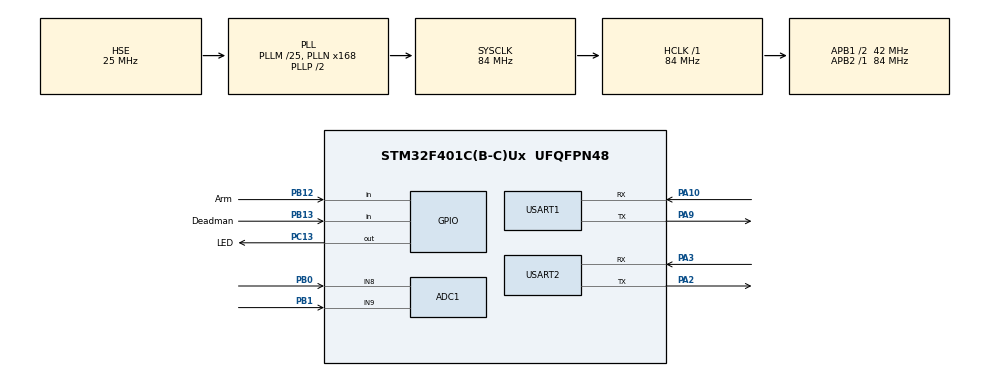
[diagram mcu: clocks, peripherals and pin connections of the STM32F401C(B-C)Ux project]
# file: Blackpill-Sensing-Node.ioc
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ADC1.Channel-0\#ChannelRegularConversion=ADC_CHANNEL_9
ADC1.Channel-1\#ChannelRegularConversion=ADC_CHANNEL_8
ADC1.DiscontinuousConvMode=ENABLE
ADC1.NbrOfDiscConversion=1
ADC1.EOCSelection=ADC_EOC_SINGLE_CONV
ADC1.NbrOfConversion=2
ADC1.NbrOfConversionFlag=1
ADC1.Rank-0\#ChannelRegularConversion=1
ADC1.Rank-1\#ChannelRegularConversion=2
ADC1.SamplingTime-0\#ChannelRegularConversion=ADC_SAMPLETIME_84CYCLES
ADC1.SamplingTime-1\#ChannelRegularConversion=ADC_SAMPLETIME_84CYCLES
ADC1.ScanConvMode=ENABLE
ADC1.master=1
FREERTOS.Tasks01=defaultTask,24,128,StartDefaultTask,Default,NULL,Dynamic,NULL,NULL
Mcu.Family=STM32F4
Mcu.Name=STM32F401C(B-C)Ux
Mcu.Package=UFQFPN48
NVIC.PriorityGroup=NVIC_PRIORITYGROUP_4
NVIC.TIM1_TRG_COM_TIM11_IRQn=true\:15\:0\:false\:false\:true\:false\:false\:true\:true
NVIC.TimeBase=TIM1_TRG_COM_TIM11_IRQn
NVIC.TimeBaseIP=TIM11
NVIC.USART1_IRQn=true\:5\:0\:false\:false\:true\:true\:true\:true\:true
PA10.Mode=Asynchronous
PA10.GPIO_PuPd=GPIO_PULLUP
PA10.Signal=USART1_RX
PA13.Mode=Serial_Wire
PA13.Signal=SYS_JTMS-SWDIO
PA14.Mode=Serial_Wire
PA14.Signal=SYS_JTCK-SWCLK
PA2.Mode=Asynchronous
PA2.Signal=USART2_TX
PA3.Mode=Asynchronous
PA3.Signal=USART2_RX
PA9.Mode=Asynchronous
PA9.Signal=USART1_TX
PB0.Signal=ADCx_IN8
PB1.Signal=ADCx_IN9
PB12.GPIO_Label=Arm
PB12.GPIO_PuPd=GPIO_PULLUP
PB12.Signal=GPIO_Input
PB13.GPIO_Label=Deadman
PB13.GPIO_PuPd=GPIO_PULLUP
PB13.Signal=GPIO_Input
PC13-ANTI_TAMP.GPIO_Label=LED
PC13-ANTI_TAMP.PinState=GPIO_PIN_SET
PC13-ANTI_TAMP.Signal=GPIO_Output
PH0\ -\ OSC_IN.Mode=HSE-External-Oscillator
PH0\ -\ OSC_IN.Signal=RCC_OSC_IN
PH1\ -\ OSC_OUT.Mode=HSE-External-Oscillator
PH1\ -\ OSC_OUT.Signal=RCC_OSC_OUT
ProjectManager.HeapSize=0x200
ProjectManager.StackSize=0x400
ProjectManager.TargetToolchain=EWARM V8.50
RCC.48MHZClocksFreq_Value=42000000
RCC.AHBFreq_Value=84000000
RCC.APB1CLKDivider=RCC_HCLK_DIV2
RCC.APB1Freq_Value=42000000
RCC.APB1TimFreq_Value=84000000
RCC.APB2Freq_Value=84000000
RCC.APB2TimFreq_Value=84000000
RCC.CortexFreq_Value=84000000
RCC.HCLKFreq_Value=84000000
RCC.HSE_VALUE=25000000
RCC.HSI_VALUE=16000000
RCC.LSE_VALUE=32768
RCC.PLLM=25
RCC.PLLN=168
RCC.PLLSourceVirtual=RCC_PLLSOURCE_HSE
RCC.SYSCLKFreq_VALUE=84000000
RCC.SYSCLKSource=RCC_SYSCLKSOURCE_PLLCLK
RCC.VCOOutputFreq_Value=168000000
SH.ADCx_IN8.0=ADC1_IN8,IN8
SH.ADCx_IN9.0=ADC1_IN9,IN9
USART1.VirtualMode=VM_ASYNC
USART2.VirtualMode=VM_ASYNC
VP_FREERTOS_VS_CMSIS_V2.Mode=CMSIS_V2
VP_SYS_VS_tim11.Mode=TIM11
board=custom

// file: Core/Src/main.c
/* USER CODE BEGIN Header */
/**
  ******************************************************************************
  * @file           : main.c
  * @brief          : Main program body
  ******************************************************************************
  * @attention
  *
  * Copyright (c) 2026 STMicroelectronics.
  * All rights reserved.
  *
  * This software is licensed under terms that can be found in the LICENSE file
  * in the root directory of this software component.
  * If no LICENSE file comes with this software, it is provided AS-IS.
  *
  ******************************************************************************
  */
/* USER CODE END Header */
#include "main.h"
#include "cmsis_os.h"

/* USER CODE BEGIN Includes */
#include "app.h"
#include "joystick_diag.h"
/* USER CODE END Includes */

ADC_HandleTypeDef hadc1;

UART_HandleTypeDef huart1;
UART_HandleTypeDef huart2;

/* Definitions for defaultTask */
osThreadId_t defaultTaskHandle;
const osThreadAttr_t defaultTask_attributes = {
  .name = "defaultTask",
  .stack_size = 3072U,
  .priority = (osPriority_t) osPriorityNormal,
};

void SystemClock_Config(void);
static void MX_GPIO_Init(void);
static void MX_ADC1_Init(void);
static void MX_USART1_UART_Init(void);
static void MX_USART2_UART_Init(void);
void StartDefaultTask(void *argument);

int main(void)
{

  /* MCU Configuration--------------------------------------------------------*/

  /* Reset of all peripherals, Initializes the Flash interface and the Systick. */
  HAL_Init();

  /* Configure the system clock */
  SystemClock_Config();

  /* Initialize all configured peripherals */
  MX_GPIO_Init();
  MX_ADC1_Init();
  MX_USART1_UART_Init();
  MX_USART2_UART_Init();
  /* USER CODE BEGIN 2 */
  App_DebugInit();
  JoyDiag_Init();

  /* USER CODE END 2 */

  /* Init scheduler */
  osKernelInitialize();

  /* Create the thread(s) */
  /* creation of defaultTask */
  defaultTaskHandle = osThreadNew(StartDefaultTask, NULL, &defaultTask_attributes);

  /* USER CODE BEGIN RTOS_THREADS */
  /* add threads, ... */
  App_Init();
  /* USER CODE END RTOS_THREADS */

  /* Start scheduler */
  osKernelStart();

  /* We should never get here as control is now taken by the scheduler */

  /* Infinite loop */
  while (1)
  {

  }
}

void SystemClock_Config(void)
{
  RCC_OscInitTypeDef RCC_OscInitStruct = {0};
  RCC_ClkInitTypeDef RCC_ClkInitStruct = {0};

  /** Configure the main internal regulator output voltage
  */
  __HAL_RCC_PWR_CLK_ENABLE();
  __HAL_PWR_VOLTAGESCALING_CONFIG(PWR_REGULATOR_VOLTAGE_SCALE2);

  /** Initializes the RCC Oscillators according to the specified parameters
  * in the RCC_OscInitTypeDef structure.
  */
  RCC_OscInitStruct.OscillatorType = RCC_OSCILLATORTYPE_HSE;
  RCC_OscInitStruct.HSEState = RCC_HSE_ON;
  RCC_OscInitStruct.PLL.PLLState = RCC_PLL_ON;
  RCC_OscInitStruct.PLL.PLLSource = RCC_PLLSOURCE_HSE;
  RCC_OscInitStruct.PLL.PLLM = 25;
  RCC_OscInitStruct.PLL.PLLN = 168;
  RCC_OscInitStruct.PLL.PLLP = RCC_PLLP_DIV2;
  RCC_OscInitStruct.PLL.PLLQ = 4;
  if (HAL_RCC_OscConfig(&RCC_OscInitStruct) != HAL_OK)
  {
    Error_Handler();
  }

  /** Initializes the CPU, AHB and APB buses clocks
  */
  RCC_ClkInitStruct.ClockType = RCC_CLOCKTYPE_HCLK|RCC_CLOCKTYPE_SYSCLK
                              |RCC_CLOCKTYPE_PCLK1|RCC_CLOCKTYPE_PCLK2;
  RCC_ClkInitStruct.SYSCLKSource = RCC_SYSCLKSOURCE_PLLCLK;
  RCC_ClkInitStruct.AHBCLKDivider = RCC_SYSCLK_DIV1;
  RCC_ClkInitStruct.APB1CLKDivider = RCC_HCLK_DIV2;
  RCC_ClkInitStruct.APB2CLKDivider = RCC_HCLK_DIV1;

  if (HAL_RCC_ClockConfig(&RCC_ClkInitStruct, FLASH_LATENCY_2) != HAL_OK)
  {
    Error_Handler();
  }
}

static void MX_ADC1_Init(void)
{

  ADC_ChannelConfTypeDef sConfig = {0};

  /** Configure the global features of the ADC (Clock, Resolution, Data Alignment and number of conversion)
  */
  hadc1.Instance = ADC1;
  hadc1.Init.ClockPrescaler = ADC_CLOCK_SYNC_PCLK_DIV4;
  hadc1.Init.Resolution = ADC_RESOLUTION_12B;
  hadc1.Init.ScanConvMode = ENABLE;
  hadc1.Init.ContinuousConvMode = DISABLE;
  hadc1.Init.DiscontinuousConvMode = ENABLE;
  hadc1.Init.NbrOfDiscConversion = 1;
  hadc1.Init.ExternalTrigConvEdge = ADC_EXTERNALTRIGCONVEDGE_NONE;
  hadc1.Init.ExternalTrigConv = ADC_SOFTWARE_START;
  hadc1.Init.DataAlign = ADC_DATAALIGN_RIGHT;
  hadc1.Init.NbrOfConversion = 2;
  hadc1.Init.DMAContinuousRequests = DISABLE;
  hadc1.Init.EOCSelection = ADC_EOC_SINGLE_CONV;
  if (HAL_ADC_Init(&hadc1) != HAL_OK)
  {
    Error_Handler();
  }

  /** Configure for the selected ADC regular channel its corresponding rank in the sequencer and its sample time.
  */
  sConfig.Channel = ADC_CHANNEL_9;
  sConfig.Rank = 1;
  sConfig.SamplingTime = ADC_SAMPLETIME_84CYCLES;
  if (HAL_ADC_ConfigChannel(&hadc1, &sConfig) != HAL_OK)
  {
    Error_Handler();
  }

  /** Configure for the selected ADC regular channel its corresponding rank in the sequencer and its sample time.
  */
  sConfig.Channel = ADC_CHANNEL_8;
  sConfig.Rank = 2;
  if (HAL_ADC_ConfigChannel(&hadc1, &sConfig) != HAL_OK)
  {
    Error_Handler();
  }

}

static void MX_USART1_UART_Init(void)
{

  huart1.Instance = USART1;
  huart1.Init.BaudRate = 115200;
  huart1.Init.WordLength = UART_WORDLENGTH_8B;
  huart1.Init.StopBits = UART_STOPBITS_1;
  huart1.Init.Parity = UART_PARITY_NONE;
  huart1.Init.Mode = UART_MODE_TX_RX;
  huart1.Init.HwFlowCtl = UART_HWCONTROL_NONE;
  huart1.Init.OverSampling = UART_OVERSAMPLING_16;
  if (HAL_UART_Init(&huart1) != HAL_OK)
  {
    Error_Handler();
  }

}

static void MX_USART2_UART_Init(void)
{

  huart2.Instance = USART2;
  huart2.Init.BaudRate = 115200;
  huart2.Init.WordLength = UART_WORDLENGTH_8B;
  huart2.Init.StopBits = UART_STOPBITS_1;
  huart2.Init.Parity = UART_PARITY_NONE;
  huart2.Init.Mode = UART_MODE_TX_RX;
  huart2.Init.HwFlowCtl = UART_HWCONTROL_NONE;
  huart2.Init.OverSampling = UART_OVERSAMPLING_16;
  if (HAL_UART_Init(&huart2) != HAL_OK)
  {
    Error_Handler();
  }

}

static void MX_GPIO_Init(void)
{
  GPIO_InitTypeDef GPIO_InitStruct = {0};

  /* GPIO Ports Clock Enable */
  __HAL_RCC_GPIOC_CLK_ENABLE();
  __HAL_RCC_GPIOH_CLK_ENABLE();
  __HAL_RCC_GPIOA_CLK_ENABLE();
  __HAL_RCC_GPIOB_CLK_ENABLE();

  /*Configure GPIO pin Output Level */
  HAL_GPIO_WritePin(LED_GPIO_Port, LED_Pin, GPIO_PIN_SET);

  /*Configure GPIO pin : LED_Pin */
  GPIO_InitStruct.Pin = LED_Pin;
  GPIO_InitStruct.Mode = GPIO_MODE_OUTPUT_PP;
  GPIO_InitStruct.Pull = GPIO_NOPULL;
  GPIO_InitStruct.Speed = GPIO_SPEED_FREQ_LOW;
  HAL_GPIO_Init(LED_GPIO_Port, &GPIO_InitStruct);

  /*Configure GPIO pins : Arm_Pin Deadman_Pin */
  GPIO_InitStruct.Pin = Arm_Pin|Deadman_Pin;
  GPIO_InitStruct.Mode = GPIO_MODE_INPUT;
  GPIO_InitStruct.Pull = GPIO_PULLUP;
  HAL_GPIO_Init(GPIOB, &GPIO_InitStruct);

}

void StartDefaultTask(void *argument)
{
  /* USER CODE BEGIN 5 */
  /* Infinite loop */
  for(;;)
  {
    JoyDiag_Poll();
    App_DebugPoll();
    osDelay(10U);
  }
  /* USER CODE END 5 */
}

void HAL_TIM_PeriodElapsedCallback(TIM_HandleTypeDef *htim)
{
  if (htim->Instance == TIM11)
  {
    HAL_IncTick();
  }
}

void Error_Handler(void)
{
  __disable_irq();
  while (1)
  {
  }
}
